# CC3220SF register map
Vendor: Texas Instruments; Series: Wireless Connectivity MCU; File version: 1
CPU: CM4 r1p0, little endian, no MPU, no FPU, 8 interrupt priority bits
Registers are 32-bit, read-write, reset 0x0 unless marked. A register's access mark holds for its fields unless they carry their own. Offsets are from the block's base; [hi:lo] are bit positions; {n}, {i} and the like mark numbered series.

## UDMA
Base 0x400FF000
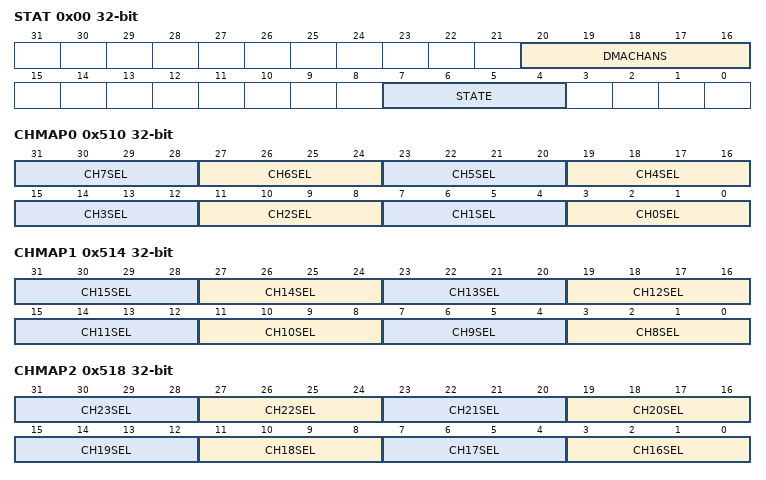
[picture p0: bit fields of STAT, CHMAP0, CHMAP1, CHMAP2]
0x00 STAT
  [20:16] DMACHANS — Available uDMA Channels Minus 1
  [7:4] STATE — Control State Machine Status 0x00000090 : UDMA_STAT_STATE_DONE : Done 0x00000000 : UDMA_STAT_STATE_IDLE : Idle 0x00000010 : UDMA_STAT_STATE_RD_CTRL : Reading channel controller data 0x00000030 : UDMA_STAT_STATE_RD_DSTENDP : Reading destination end pointer 0x00000040 : UDMA_STAT_STATE_RD_SRCDAT : Reading source data 0x00000020 : UDMA_STAT_STATE_RD_SRCENDP : Reading source end pointer 0x00000080 : UDMA_STAT_STATE_STALL : Stalled 0x000000A0 : UDMA_STAT_STATE_UNDEF : Undefined 0x00000060 : UDMA_STAT_STATE_WAIT : Waiting for uDMA request to clear 0x00000070 : UDMA_STAT_STATE_WR_CTRL : Writing channel controller data 0x00000050 : UDMA_STAT_STATE_WR_DSTDAT : Writing destination data
0x04 CFG
0x08 CTLBASE
  [31:10] ADDR — Channel Control Base Address
0x0C ALTBASE
0x10 WAITSTAT
0x14 SWREQ
0x18 USEBURSTSET
0x1C USEBURSTCLR
0x20 REQMASKSET
0x24 REQMASKCLR
0x28 ENASET
0x2C ENACLR
0x30 ALTSET
0x34 ALTCLR
0x38 PRIOSET
0x3C PRIOCLR
0x4C ERRCLR
0x500 CHASGN
0x504 CHIS
0x510 CHMAP0
  [4n+3:4n] CH{n}SEL (n=0..7) — uDMA Channel {n} Source Select
0x514 CHMAP1
  [4n-29:4n-32] CH{n}SEL (n=8..15) — uDMA Channel {n} Source Select
0x518 CHMAP2
  [4n-61:4n-64] CH{n}SEL (n=16..23) — uDMA Channel {n} Source Select
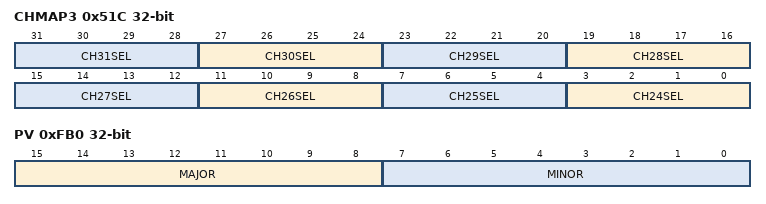
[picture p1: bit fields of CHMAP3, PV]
0x51C CHMAP3
  [4n-93:4n-96] CH{n}SEL (n=24..31) — uDMA Channel {n} Source Select
0xFB0 PV
  [15:8] MAJOR — Major Revision
  [7:0] MINOR — Minor Revision

## CAMERA
Base 0x44018000
0x00 CC_REVISION — This register contains the IP revision code ( Parallel Mode)
  [7:0] REV — IP revision [7:4] Major revision [3:0] Minor revision Examples: 0x10 for 1.0 0x21 for 2.1
0x10 CC_SYSCONFIG — This register controls the various parameters of the OCP interface (CCP and Parallel Mode)
  [4:3] S_IDLE_MODE — Slave interface power management req/ack control """00"" Force-idle. An idle request is acknoledged unconditionally" """01"" No-idle. An idle request is never acknowledged" """10"" reserved (Smart-idle not implemented)"
0x14 CC_SYSSTATUS — This register provides status information about the module excluding the interrupt status information (CCP and Parallel Mode)
0x18 CC_IRQSTATUS — The interrupt status regroups all the status of the module internal events that can generate an interrupt (CCP & Parallel Mode)
0x1C CC_IRQENABLE — The interrupt enable register allows to enable/disable the module internal sources of interrupt on an event-by-event basis (CCP & Parallel Mode)
0x40 CC_CTRL — This register controls the various parameters of the Camera Core block (CCP & Parallel Mode)
  [3:1] PAR_MODE — Sets the Protocol Mode of the Camera Core module in parallel mode (when CCP_MODE = 0) """000"" Parallel NOBT 8-bit" """001"" Parallel NOBT 10-bit" """010"" Parallel NOBT 12-bit" """011"" reserved" """100"" Parallet BT 8-bit" """101"" Parallel BT 10-bit" """110"" reserved" """111"" FIFO test mode. Refer to Table 12 - FIFO Write and Read access"
0x44 CC_CTRL_DMA — This register controls the DMA interface of the Camera Core block (CCP & Parallel Mode)
  [6:0] FIFO_THRESHOLD — Sets the threshold of the FIFO the assertion of the dmarequest line takes place when the threshold is reached. """0000000"" threshold set to 1" """0000001"" threshold set to 2" """1111111"" threshold set to 128"
0x48 CC_CTRL_XCLK — This register control the value of the clock divisor used to generate the external clock (Parallel Mode)
  [4:0] XCLK_DIV — Sets the clock divisor value for CAM_XCLK generation. based on CAM_MCK (value of CAM_MCLK is 96MHz) """00000"" CAM_XCLK Stable Low Level" Divider not enabled """00001"" CAM_XCLK Stable High Level" Divider not enabled from 2 to 30 CAM_XCLK = CAM_MCLK / XCLK_DIV """11111"" Bypass - CAM_XCLK = CAM_MCLK"
0x4C CC_FIFO_DATA — This register allows to write to the FIFO and read from the FIFO (CCP & Parallel Mode)
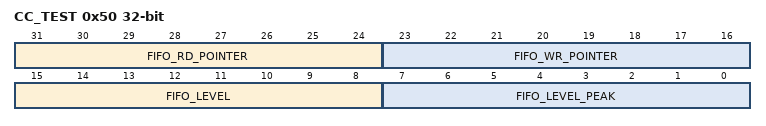
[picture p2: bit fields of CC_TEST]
0x50 CC_TEST — This register shows the status of some important variables of the camera core module (CCP & Parallel Mode)
  [31:24] FIFO_RD_POINTER — FIFO READ Pointer This field shows the value of the FIFO read pointer Expected value ranges from 0 to 127
  [23:16] FIFO_WR_POINTER — FIFO WRITE pointer This field shows the value of the FIFO write pointer Expected value ranges from 0 to 127
  [15:8] FIFO_LEVEL — FIFO level (how many 32-bit words the FIFO contains) This field shows the value of the FIFO level and can assume values from 0 to 128
  [7:0] FIFO_LEVEL_PEAK — FIFO level peak This field shows the max value of the FIFO level and can assume values from 0 to 128
0x54 CC_GEN_PAR — This register shows the values of the generic parameters of the module ****************************************************************************
  [2:0] CC_FIFO_DEPTH — Camera Core FIFO DEPTH generic parameter
